# WKUP_CTRL_MMR0_CFG0 register map
Vendor: Texas Instruments
Registers are 32-bit, read-write, reset 0x0 unless marked. A register's access mark holds for its fields unless they carry their own. Offsets are as the file gives them; [hi:lo] are bit positions; {n}, {i} and the like mark numbered series.

## WKUP_CTRL_MMR0_CFG0 (part 6 of 11)
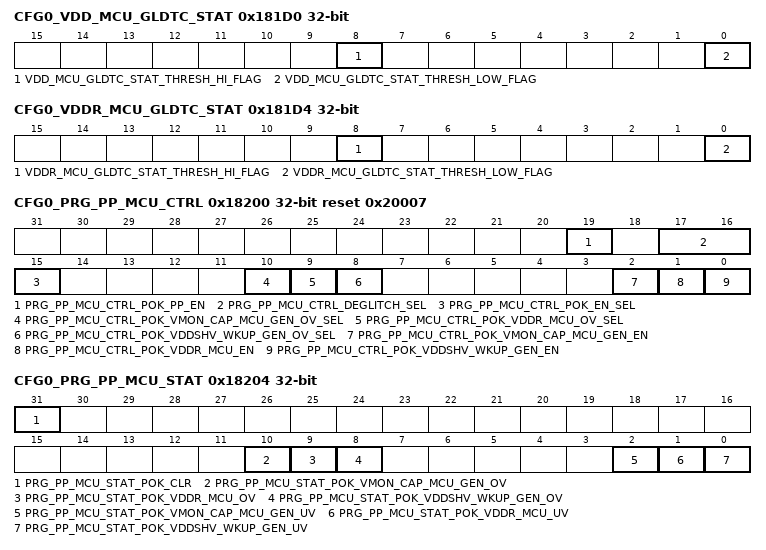
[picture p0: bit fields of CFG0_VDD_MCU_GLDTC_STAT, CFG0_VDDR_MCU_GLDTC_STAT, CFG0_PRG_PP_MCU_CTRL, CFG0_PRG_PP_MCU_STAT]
0x181D0 CFG0_VDD_MCU_GLDTC_STAT ro
  [8] VDD_MCU_GLDTC_STAT_THRESH_HI_FLAG — High voltage flag. This flag is cleared by clearing the VDD_MCU_GLDTC_CTRL_rstb bit. 0 - No high voltage detected 1 - Voltage above the high voltage threshold was detected.
  [0] VDD_MCU_GLDTC_STAT_THRESH_LOW_FLAG — Low voltage flag. This flag is cleared by clearing the VDD_MCU_GLDTC_CTRL_rstb bit. 0 - No low voltage detected 1 - Voltage below the low voltage threshold was detected.
0x181D4 CFG0_VDDR_MCU_GLDTC_STAT ro
  [8] VDDR_MCU_GLDTC_STAT_THRESH_HI_FLAG — High voltage flag. This flag is cleared by clearing the VDDR_MCU_GLDTC_CTRL_rstb bit. 0 - No high voltage detected 1 - Voltage above the high voltage threshold was detected.
  [0] VDDR_MCU_GLDTC_STAT_THRESH_LOW_FLAG — Low voltage flag. This flag is cleared by clearing the VDDR_MCU_GLDTC_CTRL_rstb bit. 0 - No low voltage detected 1 - Voltage below the low voltage threshold was detected.
0x18200 CFG0_PRG_PP_MCU_CTRL reset 0x20007
  [19] PRG_PP_MCU_CTRL_POK_PP_EN — POK ping-pong enable. When set, enables automatic switching between undervoltage and overvoltage detection on VDDSHV_WKUP_GENERAL, VDDR_MCU and VMON_CAP_MCU_GENERAL POKs. This bit has no effect if the POK's ov_sel bit = 1. 0 - No pingpong operation. UV/OV operation selected by each POK ov_sel bit 1 - Pingpong operation enabled .
  [17:16] PRG_PP_MCU_CTRL_DEGLITCH_SEL — Deglitch period for PRG_PP_MCU POKs Field values (others are reserved): 2'b00 - 5 us 2'b01 - 10 us 2'b10 - 15 us 2'b11 - 20 us
  [15] PRG_PP_MCU_CTRL_POK_EN_SEL — Select POK enable source 0 - POK enables come from hardware tie-offs 1 - POK enables come from PRG_PP_MCU_CTRL register
  [10] PRG_PP_MCU_CTRL_POK_VMON_CAP_MCU_GEN_OV_SEL — Force VMON_CAP_MCU_GENERAL POK overvoltage detection. If this bit is 0 and pok_pp_en bit is also 0 then only undervoltage detection is enabled. 0 - Undervoltage detection or UV/OV ping-pong operation 1- Overvoltage detection only
  [9] PRG_PP_MCU_CTRL_POK_VDDR_MCU_OV_SEL — Force VDDR_MCU POK overvoltage detection. If this bit is 0 and pok_pp_en bit is also 0 then only undervoltage detection is enabled. 0 - Undervoltage detection or UV/OV ping-pong operation 1- Overvoltage detection only
  [8] PRG_PP_MCU_CTRL_POK_VDDSHV_WKUP_GEN_OV_SEL — Force VDDSHV_WKUP_GENERAL POK overvoltage detection. If this bit is 0 and pok_pp_en bit is also 0 then only undervoltage detection is enabled. 0 - Undervoltage detection or UV/OV ping-pong operation 1- Overvoltage detection only
  [2] PRG_PP_MCU_CTRL_POK_VMON_CAP_MCU_GEN_EN — Enable VMON_CAP_MCU_GENERAL POK detection 0 - POK detection disabled 1 - POK detection enabled
  [1] PRG_PP_MCU_CTRL_POK_VDDR_MCU_EN — Enable VDDR_MCU POK detection 0 - POK detection disabled 1 - POK detection enabled
  [0] PRG_PP_MCU_CTRL_POK_VDDSHV_WKUP_GEN_EN — Enable VDDSHV_WKUP_GENERAL POK detection 0 - POK detection disabled 1 - POK detection enabled
0x18204 CFG0_PRG_PP_MCU_STAT access per field
  [31] PRG_PP_MCU_STAT_POK_CLR rw — When set, resets pgood sticky bits for VDDSHV_WKUP_GENERAL, VDDR_MCU, and VMON_CAP_MCU_GENERAL voltage POK detection.
  [10] PRG_PP_MCU_STAT_POK_VMON_CAP_MCU_GEN_OV ro — VMON_CAP_MCU_GENERAL overvoltage POK 0 - Voltage good 1 - Voltage above threshold
  [9] PRG_PP_MCU_STAT_POK_VDDR_MCU_OV ro — VDDR_MCU overvoltage POK 0 - Voltage good 1 - Voltage above threshold
  [8] PRG_PP_MCU_STAT_POK_VDDSHV_WKUP_GEN_OV ro — VDDSHV_WKUP_GENERAL overvoltage POK 0 - Voltage good 1 - Voltage above threshold
  [2] PRG_PP_MCU_STAT_POK_VMON_CAP_MCU_GEN_UV ro — VMON_CAP_MCU_GENERAL undervoltage POK 0 - Voltage good 1 - Voltage below threshold
  [1] PRG_PP_MCU_STAT_POK_VDDR_MCU_UV ro — VDDR_MCU undervoltage POK 0 - Voltage good 1 - Voltage below threshold
  [0] PRG_PP_MCU_STAT_POK_VDDSHV_WKUP_GEN_UV ro — VDDSHV_WKUP_GENERAL undervoltage POK 0 - Voltage good 1 - Voltage below threshold
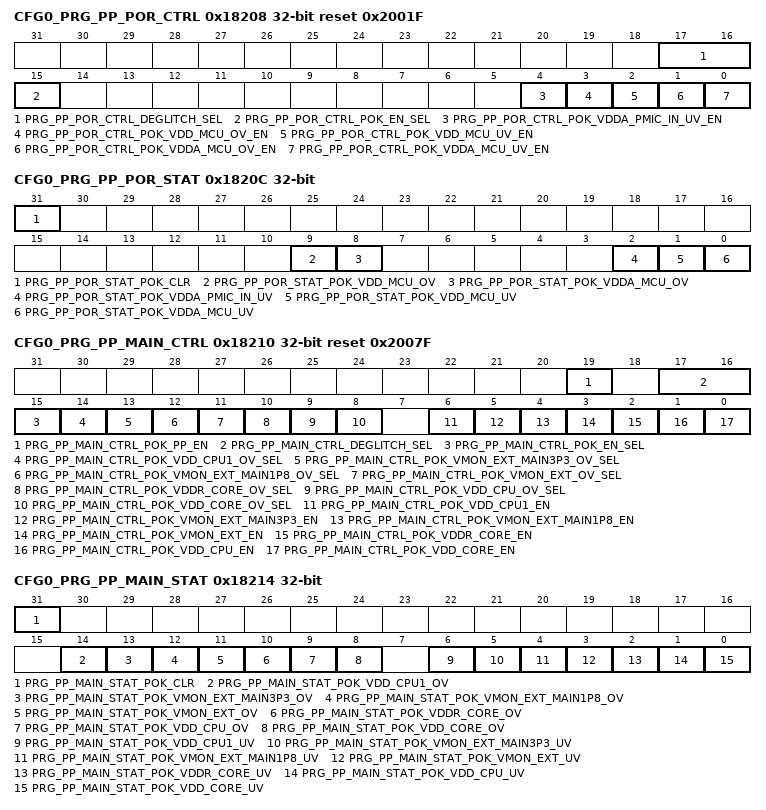
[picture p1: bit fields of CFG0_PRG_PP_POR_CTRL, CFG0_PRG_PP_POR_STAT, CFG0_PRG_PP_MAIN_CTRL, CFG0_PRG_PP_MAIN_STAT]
0x18208 CFG0_PRG_PP_POR_CTRL reset 0x2001F
  [17:16] PRG_PP_POR_CTRL_DEGLITCH_SEL — Deglitch period for PRG_PP_POR POKs Field values (others are reserved): 2'b00 - 5 us 2'b01 - 10 us 2'b10 - 15 us 2'b11 - 20 us
  [15] PRG_PP_POR_CTRL_POK_EN_SEL — Select POK enable source 0 - POK enables come from hardware tie-offs 1 - POK enables come from PRG_PP_POR_CTRL register
  [4] PRG_PP_POR_CTRL_POK_VDDA_PMIC_IN_UV_EN — Enable VDDA_PMIC_IN undervoltage POK detection 0 - POK detection disabled 1 - POK detection enabled
  [3] PRG_PP_POR_CTRL_POK_VDD_MCU_OV_EN — Enable VDD_MCU overvoltage POK detection 0 - POK detection disabled 1 - POK detection enabled
  [2] PRG_PP_POR_CTRL_POK_VDD_MCU_UV_EN — Enable VDD_MCU undervoltage POK detection 0 - POK detection disabled 1 - POK detection enabled
  [1] PRG_PP_POR_CTRL_POK_VDDA_MCU_OV_EN — Enable 1.8V VDDA_MCU overvoltage POK detection 0 - POK detection disabled 1 - POK detection enabled
  [0] PRG_PP_POR_CTRL_POK_VDDA_MCU_UV_EN — Enable 1.8V VDDA_MCU undervoltage POK detection 0 - POK detection disabled 1 - POK detection enabled
0x1820C CFG0_PRG_PP_POR_STAT access per field
  [31] PRG_PP_POR_STAT_POK_CLR rw — When set, resets pgood sticky bits for VDDA_MCU, VDD_MCU, and VDDA_PMIC_IN voltage POK detection.
  [9] PRG_PP_POR_STAT_POK_VDD_MCU_OV ro — VDD_MCU overvoltage POK detection 0 - Voltage good 1 - Voltage above threshold
  [8] PRG_PP_POR_STAT_POK_VDDA_MCU_OV ro — 1.8V VDDA_MCU overvoltage POK detection 0 - Voltage good 1 - Voltage above threshold
  [2] PRG_PP_POR_STAT_POK_VDDA_PMIC_IN_UV ro — VDDA_PMIC_IN undervoltage POK detection 0 - Voltage good 1 - Voltage below threshold
  [1] PRG_PP_POR_STAT_POK_VDD_MCU_UV ro — VDD_MCU undervoltage POK detection 0 - Voltage good 1 - Voltage below threshold
  [0] PRG_PP_POR_STAT_POK_VDDA_MCU_UV ro — 1.8V VDDA_MCU undervoltage POK detection 0 - Voltage good 1 - Voltage below threshold
0x18210 CFG0_PRG_PP_MAIN_CTRL reset 0x2007F
  [19] PRG_PP_MAIN_CTRL_POK_PP_EN — POK ping-pong enable. When set, enables automatic switching between undervoltage and overvoltage detection on VDD_CORE, VDD_CPU, VDDR_CORE, VMON_EXT, VMON_EXT_MAIN1P8 and VMON_EXT_MAIN3P3. This bit has no effect if the POK's ov_sel bit = 1. 0 - No pingpong operation. UV/OV operation selected by each POK ov_sel bit 1 - Pingpong operation enabled .
  [17:16] PRG_PP_MAIN_CTRL_DEGLITCH_SEL — Deglitch period for PRG_PP_MAIN POKs Field values (others are reserved): 2'b00 - 5 us 2'b01 - 10 us 2'b10 - 15 us 2'b11 - 20 us
  [15] PRG_PP_MAIN_CTRL_POK_EN_SEL — Select POK enable source 0 - POK enables come from hardware tie-offs 1 - POK enables come from PRG_PP_MAIN_CTRL register
  [14] PRG_PP_MAIN_CTRL_POK_VDD_CPU1_OV_SEL — Force VDD_CPU1 POK overvoltage detection. If this bit is 0 and pok_pp_en bit is also 0 then only undervoltage detection is enabled. 0 - Undervoltage detection or UV/OV ping-pong operation 1- Overvoltage detection only
  [13] PRG_PP_MAIN_CTRL_POK_VMON_EXT_MAIN3P3_OV_SEL — Force VMON_EXT_MAIN 3.3V POK overvoltage detection. If this bit is 0 and pok_pp_en bit is also 0 then only undervoltage detection is enabled. 0 - Undervoltage detection or UV/OV ping-pong operation 1- Overvoltage detection only
  [12] PRG_PP_MAIN_CTRL_POK_VMON_EXT_MAIN1P8_OV_SEL — Force VMON_EXT_MAIN 1.8V POK overvoltage detection. If this bit is 0 and pok_pp_en bit is also 0 then only undervoltage detection is enabled. 0 - Undervoltage detection or UV/OV ping-pong operation 1- Overvoltage detection only
  [11] PRG_PP_MAIN_CTRL_POK_VMON_EXT_OV_SEL — Force VMON_EXT POK overvoltage detection. If this bit is 0 and pok_pp_en bit is also 0 then only undervoltage detection is enabled. 0 - Undervoltage detection or UV/OV ping-pong operation 1- Overvoltage detection only
  [10] PRG_PP_MAIN_CTRL_POK_VDDR_CORE_OV_SEL — Force VDDR_CORE POK overvoltage detection. If this bit is 0 and pok_pp_en bit is also 0 then only undervoltage detection is enabled. 0 - Undervoltage detection or UV/OV ping-pong operation 1- Overvoltage detection only
  [9] PRG_PP_MAIN_CTRL_POK_VDD_CPU_OV_SEL — Force VDD_CPU POK overvoltage detection. If this bit is 0 and pok_pp_en bit is also 0 then only undervoltage detection is enabled. 0 - Undervoltage detection or UV/OV ping-pong operation 1- Overvoltage detection only
  [8] PRG_PP_MAIN_CTRL_POK_VDD_CORE_OV_SEL — Force VDD_CORE POK overvoltage detection. If this bit is 0 and pok_pp_en bit is also 0 then only undervoltage detection is enabled. 0 - Undervoltage detection or UV/OV ping-pong operation 1- Overvoltage detection only
  [6] PRG_PP_MAIN_CTRL_POK_VDD_CPU1_EN — Enable VDD_CPU1 POK detection 0 - POK detection disabled 1 - POK detection enabled
  [5] PRG_PP_MAIN_CTRL_POK_VMON_EXT_MAIN3P3_EN — Enable VMON_EXT_MAIN 3.3V POK detection 0 - POK detection disabled 1 - POK detection enabled
  [4] PRG_PP_MAIN_CTRL_POK_VMON_EXT_MAIN1P8_EN — Enable VMON_EXT_MAIN 1.8V POK detection 0 - POK detection disabled 1 - POK detection enabled
  [3] PRG_PP_MAIN_CTRL_POK_VMON_EXT_EN — Enable VMON_EXT POK detection 0 - POK detection disabled 1 - POK detection enabled
  [2] PRG_PP_MAIN_CTRL_POK_VDDR_CORE_EN — Enable VDDR_CORE POK detection 0 - POK detection disabled 1 - POK detection enabled
  [1] PRG_PP_MAIN_CTRL_POK_VDD_CPU_EN — Enable VDD_CPU POK detection 0 - POK detection disabled 1 - POK detection enabled
  [0] PRG_PP_MAIN_CTRL_POK_VDD_CORE_EN — Enable VDD_CORE POK detection 0 - POK detection disabled 1 - POK detection enabled
0x18214 CFG0_PRG_PP_MAIN_STAT access per field
  [31] PRG_PP_MAIN_STAT_POK_CLR rw — When set, resets pgood sticky bits for VDD_CORE, VDD_CPU, VDDR_CORE, VMON_EXT, VMON_EXT_MAIN1P8, and VMON_EXT_MAIN3P3 voltage POK detection.
  [14] PRG_PP_MAIN_STAT_POK_VDD_CPU1_OV ro — VDD_CPU1 overvoltage POK 0 - Voltage good 1 - Voltage above threshold
  [13] PRG_PP_MAIN_STAT_POK_VMON_EXT_MAIN3P3_OV ro — VMON_EXT_MAIN 3.3V overvoltage POK 0 - Voltage good 1 - Voltage above threshold
  [12] PRG_PP_MAIN_STAT_POK_VMON_EXT_MAIN1P8_OV ro — VMON_EXT_MAIN 1.8V overvoltage POK 0 - Voltage good 1 - Voltage above threshold
  [11] PRG_PP_MAIN_STAT_POK_VMON_EXT_OV ro — VMON_EXT overvoltage POK 0 - Voltage good 1 - Voltage above threshold
  [10] PRG_PP_MAIN_STAT_POK_VDDR_CORE_OV ro — VDDR_CORE overvoltage POK 0 - Voltage good 1 - Voltage above threshold
  [9] PRG_PP_MAIN_STAT_POK_VDD_CPU_OV ro — VDD_CPU overvoltage POK 0 - Voltage good 1 - Voltage above threshold
  [8] PRG_PP_MAIN_STAT_POK_VDD_CORE_OV ro — VDD_CORE overvoltage POK 0 - Voltage good 1 - Voltage above threshold
  [6] PRG_PP_MAIN_STAT_POK_VDD_CPU1_UV ro — VDD_CPU1 undervoltage POK 0 - Voltage good 1 - Voltage below threshold
  [5] PRG_PP_MAIN_STAT_POK_VMON_EXT_MAIN3P3_UV ro — VMON_EXT_MAIN 3.3V undervoltage POK 0 - Voltage good 1 - Voltage below threshold
  [4] PRG_PP_MAIN_STAT_POK_VMON_EXT_MAIN1P8_UV ro — VMON_EXT_MAIN 1.8V undervoltage POK 0 - Voltage good 1 - Voltage below threshold
  [3] PRG_PP_MAIN_STAT_POK_VMON_EXT_UV ro — VMON_EXT undervoltage POK 0 - Voltage good 1 - Voltage below threshold
  [2] PRG_PP_MAIN_STAT_POK_VDDR_CORE_UV ro — VDDR_CORE undervoltage POK 0 - Voltage good 1 - Voltage below threshold
  [1] PRG_PP_MAIN_STAT_POK_VDD_CPU_UV ro — VDD_CPU undervoltage POK 0 - Voltage good 1 - Voltage below threshold
  [0] PRG_PP_MAIN_STAT_POK_VDD_CORE_UV ro — VDD_CORE undervoltage POK 0 - Voltage good 1 - Voltage below threshold
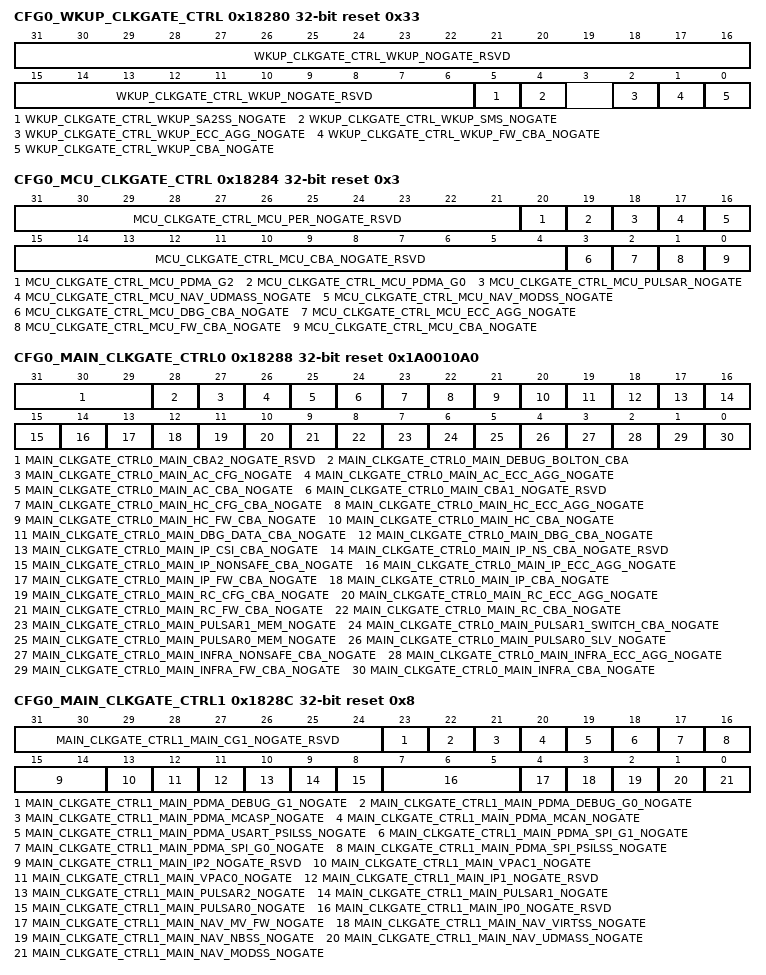
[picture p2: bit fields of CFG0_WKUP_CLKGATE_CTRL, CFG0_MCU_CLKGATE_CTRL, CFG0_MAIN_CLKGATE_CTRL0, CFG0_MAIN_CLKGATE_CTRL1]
0x18280 CFG0_WKUP_CLKGATE_CTRL reset 0x33
  [31:6] WKUP_CLKGATE_CTRL_WKUP_NOGATE_RSVD — WKUP reserved clock gate disable. These bits should remain unchanged (written only with their default value) to maintain compatibility with future devices. 0 - Clocks are gated on idle for power savings 1 - Clocks are not gated on idle, power saving disabled
  [5] WKUP_CLKGATE_CTRL_WKUP_SA2SS_NOGATE — WKUP SA2SS clock gate disable 0 - Clocks are gated on idle for power savings 1 - Clocks are not gated on idle, power saving disabled
  [4] WKUP_CLKGATE_CTRL_WKUP_SMS_NOGATE — WKUP SMS clock gate disable 0 - Clocks are gated on idle for power savings 1 - Clocks are not gated on idle, power saving disabled
  [2] WKUP_CLKGATE_CTRL_WKUP_ECC_AGG_NOGATE — WKUP ECC Aggregator clock gate disable 0 - Clocks are gated on idle for power savings 1 - Clocks are not gated on idle, power saving disabled
  [1] WKUP_CLKGATE_CTRL_WKUP_FW_CBA_NOGATE — WKUP domain Firewall bus (wkup_fw_cbass) clock gate disable 0 - Clocks are gated on idle for power savings 1 - Clocks are not gated on idle, power saving disabled
  [0] WKUP_CLKGATE_CTRL_WKUP_CBA_NOGATE — WKUP domain Data bus (wkup_cbass) clock gate disable 0 - Clocks are gated on idle for power savings 1 - Clocks are not gated on idle, power saving disabled
0x18284 CFG0_MCU_CLKGATE_CTRL reset 0x3
  [31:21] MCU_CLKGATE_CTRL_MCU_PER_NOGATE_RSVD — MCU reserved clock gate disable. These bits should remain unchanged (written only with their default value) to maintain compatibility with future devices. 0 - Clocks are gated on idle for power savings 1 - Clocks are not gated on idle, power saving disabled
  [20] MCU_CLKGATE_CTRL_MCU_PDMA_G2 — MCU domain MCAN1/USART0 PDMA clock gate disable. 0 - Clocks are gated on idle for power savings 1 - Clocks are not gated on idle, power saving disabled
  [19] MCU_CLKGATE_CTRL_MCU_PDMA_G0 — MCU domain MCAN0/SPI0 PDMA clock gate disable. 0 - Clocks are gated on idle for power savings 1 - Clocks are not gated on idle, power saving disabled
  [18] MCU_CLKGATE_CTRL_MCU_PULSAR_NOGATE — MCU domain Pulsar clock gate disable. 0 - Clocks are gated on idle for power savings 1 - Clocks are not gated on idle, power saving disabled
  [17] MCU_CLKGATE_CTRL_MCU_NAV_UDMASS_NOGATE — MCU NavSS UDMA interface clock gate disable. 0 - Clocks are gated on idle for power savings 1 - Clocks are not gated on idle, power saving disabled
  [16] MCU_CLKGATE_CTRL_MCU_NAV_MODSS_NOGATE — MCU NavSS MODSS interface clock gate disable. 0 - Clocks are gated on idle for power savings 1 - Clocks are not gated on idle, power saving disabled
  [15:4] MCU_CLKGATE_CTRL_MCU_CBA_NOGATE_RSVD — MCU reserved clock gate disable. These bits should remain unchanged (written only with their default value) to maintain compatibility with future devices. 0 - Clocks are gated on idle for power savings 1 - Clocks are not gated on idle, power saving disabled
  [3] MCU_CLKGATE_CTRL_MCU_DBG_CBA_NOGATE — MCU domain Debug bus (mcu_dbg_cbass) clock gate disable. 0 - Clocks are gated on idle for power savings 1 - Clocks are not gated on idle, power saving disabled
  [2] MCU_CLKGATE_CTRL_MCU_ECC_AGG_NOGATE — MCU ECC Aggregator clock gate disable 0 - Clocks are gated on idle for power savings 1 - Clocks are not gated on idle, power saving disabled
  [1] MCU_CLKGATE_CTRL_MCU_FW_CBA_NOGATE — MCU domain Firewall bus (mcu_fw_cbass) clock gate disable. 0 - Clocks are gated on idle for power savings 1 - Clocks are not gated on idle, power saving disabled
  [0] MCU_CLKGATE_CTRL_MCU_CBA_NOGATE — MCU domain Data bus (mcu_cbass) clock gate disable. 0 - Clocks are gated on idle for power savings 1 - Clocks are not gated on idle, power saving disabled
0x18288 CFG0_MAIN_CLKGATE_CTRL0 reset 0x1A0010A0
  [31:29] MAIN_CLKGATE_CTRL0_MAIN_CBA2_NOGATE_RSVD — MAIN CBA reserved clock gate disable. These bits should remain unchanged (written only with their default value) to maintain compatibility with future devices. 0 - Clocks are gated on idle for power savings 1 - Clocks are not gated on idle, power saving disabled
  [28] MAIN_CLKGATE_CTRL0_MAIN_DEBUG_BOLTON_CBA — MAIN domain debug bolton bus (debug_bolton_cbass) clock gate disable. 0 - Clocks are gated on idle for power savings 1 - Clocks are not gated on idle, power saving disabled
  [27] MAIN_CLKGATE_CTRL0_MAIN_AC_CFG_NOGATE — MAIN domain AC Configuration bus (ac_cfg_fw_cbass) clock gate disable. 0 - Clocks are gated on idle for power savings 1 - Clocks are not gated on idle, power saving disabled
  [26] MAIN_CLKGATE_CTRL0_MAIN_AC_ECC_AGG_NOGATE — MAIN domain AC ECC aggregator bus (ac_pipe_ecc_aggr) clock gate disable. 0 - Clocks are gated on idle for power savings 1 - Clocks are not gated on idle, power saving disabled
  [25] MAIN_CLKGATE_CTRL0_MAIN_AC_CBA_NOGATE — MAIN domain AC Firewall bus (ac_pipe_cbass_main_fw_cbass_0) clock gate disable. 0 - Clocks are gated on idle for power savings 1 - Clocks are not gated on idle, power saving disabled
  [24] MAIN_CLKGATE_CTRL0_MAIN_CBA1_NOGATE_RSVD — MAIN CBA reserved clock gate disable. These bits should remain unchanged (written only with their default value) to maintain compatibility with future devices. 0 - Clocks are gated on idle for power savings 1 - Clocks are not gated on idle, power saving disabled
  [23] MAIN_CLKGATE_CTRL0_MAIN_HC_CFG_CBA_NOGATE — MAIN domain HC Configuration bus (hc_cfg_cbass_0) clock gate disable. 0 - Clocks are gated on idle for power savings 1 - Clocks are not gated on idle, power saving disabled
  [22] MAIN_CLKGATE_CTRL0_MAIN_HC_ECC_AGG_NOGATE — MAIN domain HC ECC aggregator (nogate) clock gate disable. 0 - Clocks are gated on idle for power savings 1 - Clocks are not gated on idle, power saving disabled
  [21] MAIN_CLKGATE_CTRL0_MAIN_HC_FW_CBA_NOGATE — MAIN domain HC Firewall bus (main_hc2_fw_cbass_0) clock gate disable. 0 - Clocks are gated on idle for power savings 1 - Clocks are not gated on idle, power saving disabled
  [20] MAIN_CLKGATE_CTRL0_MAIN_HC_CBA_NOGATE — MAIN domain HC Data bus (hc2_cbass_0) clock gate disable. 0 - Clocks are gated on idle for power savings 1 - Clocks are not gated on idle, power saving disabled
  [19] MAIN_CLKGATE_CTRL0_MAIN_DBG_DATA_CBA_NOGATE — MAIN domain Debug Data bus (debug_cbass) clock gate disable. 0 - Clocks are gated on idle for power savings 1 - Clocks are not gated on idle, power saving disabled
  [18] MAIN_CLKGATE_CTRL0_MAIN_DBG_CBA_NOGATE — MAIN domain Debug bus (debug_cbass_wrap_main_0) clock gate disable. 0 - Clocks are gated on idle for power savings 1 - Clocks are not gated on idle, power saving disabled
  [17] MAIN_CLKGATE_CTRL0_MAIN_IP_CSI_CBA_NOGATE — MAIN domain CSI bus (csi_cbass_0) clock gate disable. 0 - Clocks are gated on idle for power savings 1 - Clocks are not gated on idle, power saving disabled
  [16] MAIN_CLKGATE_CTRL0_MAIN_IP_NS_CBA_NOGATE_RSVD — MAIN nonsafety CBA reserved clock gate disable. These bits should remain unchanged (written only with their default value) to maintain compatibility with future devices. 0 - Clocks are gated on idle for power savings 1 - Clocks are not gated on idle, power saving disabled
  [15] MAIN_CLKGATE_CTRL0_MAIN_IP_NONSAFE_CBA_NOGATE — MAIN domain Interface Peripheral nonsafety IP bus (ipphy_cbass_0) clock gate disable. 0 - Clocks are gated on idle for power savings 1 - Clocks are not gated on idle, power saving disabled
  [14] MAIN_CLKGATE_CTRL0_MAIN_IP_ECC_AGG_NOGATE — MAIN domain Interface Peripheral ECC aggregator (main_spi0_g0_main_0_ecc_aggr_main_0) clock gate disable. 0 - Clocks are gated on idle for power savings 1 - Clocks are not gated on idle, power saving disabled
  [13] MAIN_CLKGATE_CTRL0_MAIN_IP_FW_CBA_NOGATE — MAIN domain Interface Peripheral Firewall bus (ipphy_cbass_main_fw_cbass) clock gate disable. 0 - Clocks are gated on idle for power savings 1 - Clocks are not gated on idle, power saving disabled
  [12] MAIN_CLKGATE_CTRL0_MAIN_IP_CBA_NOGATE — MAIN domain Interface Peripheral bus (ipphy_safe_cbass_0) clock gate disable. 0 - Clocks are gated on idle for power savings 1 - Clocks are not gated on idle, power saving disabled
  [11] MAIN_CLKGATE_CTRL0_MAIN_RC_CFG_CBA_NOGATE — MAIN domain RC Configuration bus (rc_cfg_cbass_0) clock gate disable. 0 - Clocks are gated on idle for power savings 1 - Clocks are not gated on idle, power saving disabled
  [10] MAIN_CLKGATE_CTRL0_MAIN_RC_ECC_AGG_NOGATE — MAIN domain RC ECC aggregator (main_rc_ecc_aggr_main_0) clock gate disable. 0 - Clocks are gated on idle for power savings 1 - Clocks are not gated on idle, power saving disabled
  [9] MAIN_CLKGATE_CTRL0_MAIN_RC_FW_CBA_NOGATE — MAIN domain RC Firewall bus (rc_cbass_main_fw_cbass) clock gate disable. 0 - Clocks are gated on idle for power savings 1 - Clocks are not gated on idle, power saving disabled
  [8] MAIN_CLKGATE_CTRL0_MAIN_RC_CBA_NOGATE — MAIN domain RC Data bus (rc_cbass_0) clock gate disable. 0 - Clocks are gated on idle for power savings 1 - Clocks are not gated on idle, power saving disabled
  [7] MAIN_CLKGATE_CTRL0_MAIN_PULSAR1_MEM_NOGATE — MAIN domain Pulsar 1 memory bus (pulsar1_mem_cbass) clock gate disable. 0 - Clocks are gated on idle for power savings 1 - Clocks are not gated on idle, power saving disabled
  [6] MAIN_CLKGATE_CTRL0_MAIN_PULSAR1_SWITCH_CBA_NOGATE — MAIN domain Pulsar 1 peripheral switch bus (pulsar1_periph_switch_cbass) clock gate disable. 0 - Clocks are gated on idle for power savings 1 - Clocks are not gated on idle, power saving disabled
  [5] MAIN_CLKGATE_CTRL0_MAIN_PULSAR0_MEM_NOGATE — MAIN domain Pulsar 0 memory bus (pulsar0_mem_cbass) clock gate disable. 0 - Clocks are gated on idle for power savings 1 - Clocks are not gated on idle, power saving disabled
  [4] MAIN_CLKGATE_CTRL0_MAIN_PULSAR0_SLV_NOGATE — MAIN domain Pulsar slave bus (pulsar0_slv_cbass) clock gate disable. 0 - Clocks are gated on idle for power savings 1 - Clocks are not gated on idle, power saving disabled
  [3] MAIN_CLKGATE_CTRL0_MAIN_INFRA_NONSAFE_CBA_NOGATE — MAIN domain Infrastructure non-safety IP bus (main_infra_non_safe_cbass) clock gate disable. 0 - Clocks are gated on idle for power savings 1 - Clocks are not gated on idle, power saving disabled
  [2] MAIN_CLKGATE_CTRL0_MAIN_INFRA_ECC_AGG_NOGATE — MAIN domain Infrastructure ECC aggregator (main_infra_ecc_aggr) clock gate disable. 0 - Clocks are gated on idle for power savings 1 - Clocks are not gated on idle, power saving disabled
  [1] MAIN_CLKGATE_CTRL0_MAIN_INFRA_FW_CBA_NOGATE — MAIN domain Infrastructure Firewall bus (main_infra_fw_cbass) clock gate disable. 0 - Clocks are gated on idle for power savings 1 - Clocks are not gated on idle, power saving disabled
  [0] MAIN_CLKGATE_CTRL0_MAIN_INFRA_CBA_NOGATE — MAIN domain Infrastructure bus (main_infra_cbass) clock gate disable. 0 - Clocks are gated on idle for power savings 1 - Clocks are not gated on idle, power saving disabled
0x1828C CFG0_MAIN_CLKGATE_CTRL1 reset 0x8
  [31:24] MAIN_CLKGATE_CTRL1_MAIN_CG1_NOGATE_RSVD — MAIN PDMA clock gate disable. These bits should remain unchanged (written only with their default value) to maintain compatibility with future devices. 0 - Clocks are gated on idle for power savings 1 - Clocks are not gated on idle, power saving disabled
  [23] MAIN_CLKGATE_CTRL1_MAIN_PDMA_DEBUG_G1_NOGATE — MAIN domain PDMA Debug_G1 clock gate disable. 0 - Clocks are gated on idle for power savings 1 - Clocks are not gated on idle, power saving disabled
  [22] MAIN_CLKGATE_CTRL1_MAIN_PDMA_DEBUG_G0_NOGATE — MAIN domain PDMA Debug_G0 clock gate disable. 0 - Clocks are gated on idle for power savings 1 - Clocks are not gated on idle, power saving disabled
  [21] MAIN_CLKGATE_CTRL1_MAIN_PDMA_MCASP_NOGATE — MAIN domain PDMA MCASP clock gate disable. 0 - Clocks are gated on idle for power savings 1 - Clocks are not gated on idle, power saving disabled
  [20] MAIN_CLKGATE_CTRL1_MAIN_PDMA_MCAN_NOGATE — MAIN domain PDMA MCAN clock gate disable. 0 - Clocks are gated on idle for power savings 1 - Clocks are not gated on idle, power saving disabled
  [19] MAIN_CLKGATE_CTRL1_MAIN_PDMA_USART_PSILSS_NOGATE — MAIN domain PDMA USART PSILSS clock gate disable. 0 - Clocks are gated on idle for power savings 1 - Clocks are not gated on idle, power saving disabled
  [18] MAIN_CLKGATE_CTRL1_MAIN_PDMA_SPI_G1_NOGATE — MAIN domain PDMA SPI_G1 clock gate disable. 0 - Clocks are gated on idle for power savings 1 - Clocks are not gated on idle, power saving disabled
  [17] MAIN_CLKGATE_CTRL1_MAIN_PDMA_SPI_G0_NOGATE — MAIN domain PDMA SPI_G0 clock gate disable. 0 - Clocks are gated on idle for power savings 1 - Clocks are not gated on idle, power saving disabled
  [16] MAIN_CLKGATE_CTRL1_MAIN_PDMA_SPI_PSILSS_NOGATE — MAIN domain PDMA SPI PSILSS clock gate disable. 0 - Clocks are gated on idle for power savings 1 - Clocks are not gated on idle, power saving disabled
  [15:14] MAIN_CLKGATE_CTRL1_MAIN_IP2_NOGATE_RSVD — MAIN IP reserved clock gate disable. These bits should remain unchanged (written only with their default value) to maintain compatibility with future devices. 0 - Clocks are gated on idle for power savings 1 - Clocks are not gated on idle, power saving disabled
  [13] MAIN_CLKGATE_CTRL1_MAIN_VPAC1_NOGATE — MAIN domain VPAC 1 clock gate disable. 0 - Clocks are gated on idle for power savings 1 - Clocks are not gated on idle, power saving disabled
  [12] MAIN_CLKGATE_CTRL1_MAIN_VPAC0_NOGATE — MAIN domain VPAC 0 clock gate disable. 0 - Clocks are gated on idle for power savings 1 - Clocks are not gated on idle, power saving disabled
  [11] MAIN_CLKGATE_CTRL1_MAIN_IP1_NOGATE_RSVD — MAIN IP reserved clock gate disable. These bits should remain unchanged (written only with their default value) to maintain compatibility with future devices. 0 - Clocks are gated on idle for power savings 1 - Clocks are not gated on idle, power saving disabled
  [10] MAIN_CLKGATE_CTRL1_MAIN_PULSAR2_NOGATE — MAIN domain Pulsar 2 clock gate disable. 0 - Clocks are gated on idle for power savings 1 - Clocks are not gated on idle, power saving disabled
  [9] MAIN_CLKGATE_CTRL1_MAIN_PULSAR1_NOGATE — MAIN domain Pulsar 1 clock gate disable. 0 - Clocks are gated on idle for power savings 1 - Clocks are not gated on idle, power saving disabled
  [8] MAIN_CLKGATE_CTRL1_MAIN_PULSAR0_NOGATE — MAIN domain Pulsar 0 clock gate disable. 0 - Clocks are gated on idle for power savings 1 - Clocks are not gated on idle, power saving disabled
  [7:5] MAIN_CLKGATE_CTRL1_MAIN_IP0_NOGATE_RSVD — MAIN IP reserved clock gate disable. These bits should remain unchanged (written only with their default value) to maintain compatibility with future devices. 0 - Clocks are gated on idle for power savings 1 - Clocks are not gated on idle, power saving disabled
  [4] MAIN_CLKGATE_CTRL1_MAIN_NAV_MV_FW_NOGATE — MAIN NavSS Mod/Virt Firewall interface clock gate disable. 0 - Clocks are gated on idle for power savings 1 - Clocks are not gated on idle, power saving disabled
  [3] MAIN_CLKGATE_CTRL1_MAIN_NAV_VIRTSS_NOGATE — MAIN NavSS VIRTSS interface clock gate disable. 0 - Clocks are gated on idle for power savings 1 - Clocks are not gated on idle, power saving disabled
  [2] MAIN_CLKGATE_CTRL1_MAIN_NAV_NBSS_NOGATE — MAIN NavSS NB interface clock gate disable. 0 - Clocks are gated on idle for power savings 1 - Clocks are not gated on idle, power saving disabled
  [1] MAIN_CLKGATE_CTRL1_MAIN_NAV_UDMASS_NOGATE — Main NavSS UDMA interface clock gate disable. 0 - Clocks are gated on idle for power savings 1 - Clocks are not gated on idle, power saving disabled
  [0] MAIN_CLKGATE_CTRL1_MAIN_NAV_MODSS_NOGATE — MAIN NavSS MODSS interface clock gate disable. 0 - Clocks are gated on idle for power savings 1 - Clocks are not gated on idle, power saving disabled
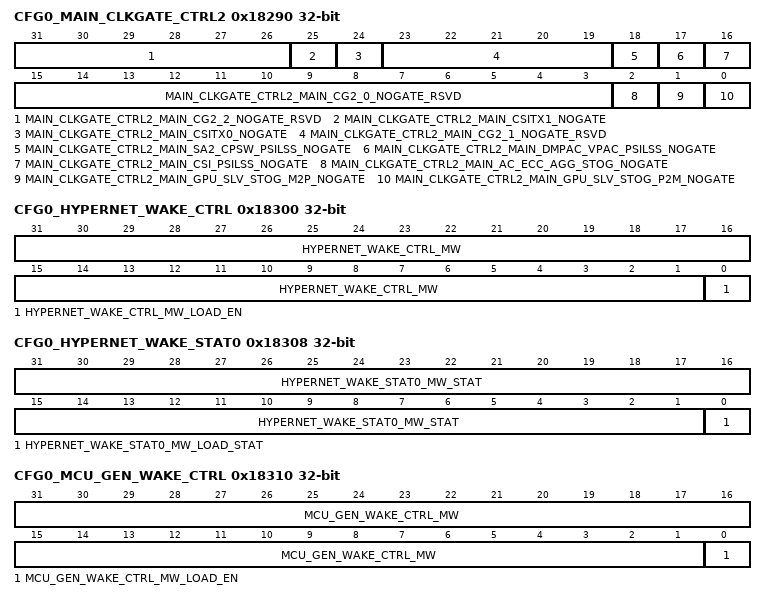
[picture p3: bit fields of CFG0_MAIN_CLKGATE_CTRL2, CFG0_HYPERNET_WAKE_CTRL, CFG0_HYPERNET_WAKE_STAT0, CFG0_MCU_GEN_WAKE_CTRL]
0x18290 CFG0_MAIN_CLKGATE_CTRL2
  [31:26] MAIN_CLKGATE_CTRL2_MAIN_CG2_2_NOGATE_RSVD — MAIN domain spare clock gate disable. These bits should remain unchanged (written only with their default value) to maintain compatibility with future devices. 0 - Clocks are gated on idle for power savings 1 - Clocks are not gated on idle, power saving disabled
  [25] MAIN_CLKGATE_CTRL2_MAIN_CSITX1_NOGATE — MAIN domain CSI_TX1 clock gate disable. 0 - Clocks are gated on idle for power savings 1 - Clocks are not gated on idle, power saving disabled
  [24] MAIN_CLKGATE_CTRL2_MAIN_CSITX0_NOGATE — MAIN domain CSI_TX0 clock gate disable. 0 - Clocks are gated on idle for power savings 1 - Clocks are not gated on idle, power saving disabled
  [23:19] MAIN_CLKGATE_CTRL2_MAIN_CG2_1_NOGATE_RSVD — MAIN domain spare clock gate disable. These bits should remain unchanged (written only with their default value) to maintain compatibility with future devices. 0 - Clocks are gated on idle for power savings 1 - Clocks are not gated on idle, power saving disabled
  [18] MAIN_CLKGATE_CTRL2_MAIN_SA2_CPSW_PSILSS_NOGATE — MAIN domain SA2_UL/SPCW PSILSS clock gate disable. 0 - Clocks are gated on idle for power savings 1 - Clocks are not gated on idle, power saving disabled
  [17] MAIN_CLKGATE_CTRL2_MAIN_DMPAC_VPAC_PSILSS_NOGATE — MAIN domain DMPAC/VPAC PSILSS clock gate disable. 0 - Clocks are gated on idle for power savings 1 - Clocks are not gated on idle, power saving disabled
  [16] MAIN_CLKGATE_CTRL2_MAIN_CSI_PSILSS_NOGATE — MAIN domain CSI PSILSS clock gate disable. 0 - Clocks are gated on idle for power savings 1 - Clocks are not gated on idle, power saving disabled
  [15:3] MAIN_CLKGATE_CTRL2_MAIN_CG2_0_NOGATE_RSVD — MAIN domain spare clock gate disable. These bits should remain unchanged (written only with their default value) to maintain compatibility with future devices. 0 - Clocks are gated on idle for power savings 1 - Clocks are not gated on idle, power saving disabled
  [2] MAIN_CLKGATE_CTRL2_MAIN_AC_ECC_AGG_STOG_NOGATE — MAIN domain ac ECC aggregator Slave Timeout Gasket (main_ac_ecc_aggr_stog) clock gate disable. 0 - Clocks are gated on idle for power savings 1 - Clocks are not gated on idle, power saving disabled
  [1] MAIN_CLKGATE_CTRL2_MAIN_GPU_SLV_STOG_M2P_NOGATE — MAIN domain GPU Slave Timeout Gasket output (main_gpu_slv_stog_m2p_pwr_dis) clock gate disable. 0 - Clocks are gated on idle for power savings 1 - Clocks are not gated on idle, power saving disabled
  [0] MAIN_CLKGATE_CTRL2_MAIN_GPU_SLV_STOG_P2M_NOGATE — MAIN domain GPU Slave Timeout Gasket input (main_gpu_slv_stog_p2m_pwr_dis) clock gate disable. 0 - Clocks are gated on idle for power savings 1 - Clocks are not gated on idle, power saving disabled
0x18294 CFG0_MAIN_CLKGATE_CTRL3
  [31:0] MAIN_CLKGATE_CTRL3_MAIN_CG3_NOGATE_RSVD — MAIN domain spare clock gate disable. These bits should remain unchanged (written only with their default value) to maintain compatibility with future devices. 0 - Clocks are gated on idle for power savings 1 - Clocks are not gated on idle, power saving disabled
0x18300 CFG0_HYPERNET_WAKE_CTRL
  [31:1] HYPERNET_WAKE_CTRL_MW — HYPERNET IO magic word. This 31-bit value that enables placing of the HYPERNET I/Os into isolation for daisy-chain wakeup operation. 0x5555 - Magic word value to enable isolation when qualified with mw_load bit Others - Any other value will prevent isolation when mw_load transitions from 0 to 1.
  [0] HYPERNET_WAKE_CTRL_MW_LOAD_EN — Magic word load enable Setting this bit to 1 loads and locks the mw field for HYPERNET IO isolation. If the mw field matches the magic word value then the value is latched into the HYPERNET IO voltage domain and HYPERNET IO isolation is enabled. 0 - Unlock and do not load mw value for comparison 1 - Load and lock mw for magic word value comparison
0x18308 CFG0_HYPERNET_WAKE_STAT0 ro
  [31:1] HYPERNET_WAKE_STAT0_MW_STAT — HYPERNET magic word status Indicates the latched value of the mw field.
  [0] HYPERNET_WAKE_STAT0_MW_LOAD_STAT — Magic word load status. Indicates the latched value of the mw_load_en bit
0x1830C CFG0_HYPERNET_WAKE_STAT1 ro
  [0] HYPERNET_WAKE_STAT1_HYPERNET_IO_MODE — Indicates if HYPERNET IO wakeup mode is enabled. 0 - Not enabled (load_en not set or mw doesn't match magic word) 1 - HYPERNET IO mode enabled
0x18310 CFG0_MCU_GEN_WAKE_CTRL
  [31:1] MCU_GEN_WAKE_CTRL_MW — MCU_GENERAL IO magic word. This 31-bit value that enables placing of the MCU_GENERAL I/Os into isolation for daisy-chain wakeup operation. 0x5555 - Magic word value to enable isolation when qualified with mw_load bit Others - Any other value will prevent isolation when mw_load transitions from 0 to 1.
  [0] MCU_GEN_WAKE_CTRL_MW_LOAD_EN — Magic word load enable Setting this bit to 1 loads and locks the mw field for MCU_GENERAL IO isolation. If the mw field matches the magic word value then the value is latched into the MCU_GENERAL IO voltage domain and MCU_GENERAL IO isolation is enabled. 0 - Unlock and do not load mw value for comparison 1 - Load and lock mw for magic word value comparison
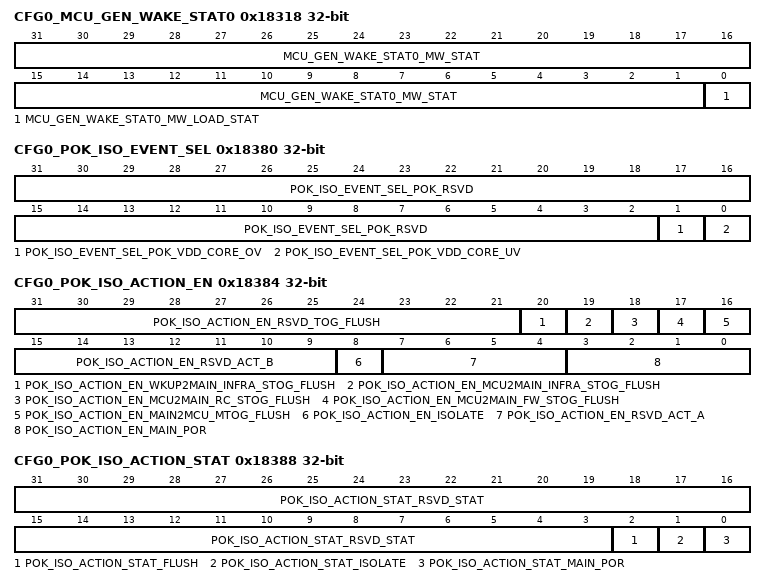
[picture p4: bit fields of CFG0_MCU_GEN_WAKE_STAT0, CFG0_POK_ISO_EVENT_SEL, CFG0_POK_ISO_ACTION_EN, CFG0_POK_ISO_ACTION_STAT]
0x18318 CFG0_MCU_GEN_WAKE_STAT0 ro
  [31:1] MCU_GEN_WAKE_STAT0_MW_STAT — MCU_GENERAL magic word status Indicates the latched value of the mw field.
  [0] MCU_GEN_WAKE_STAT0_MW_LOAD_STAT — Magic word load status. Indicates the latched value of the mw_load_en bit
0x1831C CFG0_MCU_GEN_WAKE_STAT1 ro
  [0] MCU_GEN_WAKE_STAT1_MCU_GEN_IO_MODE — Indicates if MCU_GENERAL IO wakeup mode is enabled. 0 - Not enabled (load_en not set or mw doesn't match magic word) 1 - MCU_GENERAL IO mode enabled
0x18380 CFG0_POK_ISO_EVENT_SEL
  [31:2] POK_ISO_EVENT_SEL_POK_RSVD — Reserved for future use (do not optimize out)
  [1] POK_ISO_EVENT_SEL_POK_VDD_CORE_OV — VDD_CORE overvoltage detection triggers enabled isolation actions
  [0] POK_ISO_EVENT_SEL_POK_VDD_CORE_UV — VDD_CORE undervoltage detection triggers enabled isolation actions
0x18384 CFG0_POK_ISO_ACTION_EN
  [31:21] POK_ISO_ACTION_EN_RSVD_TOG_FLUSH — Reserved timeout gasket flush enable bits. Do not optimize out 0 - Enabled POK events have no effect on this gasket 1 - Enabled POK events will assert the flush for this gasket
  [20] POK_ISO_ACTION_EN_WKUP2MAIN_INFRA_STOG_FLUSH — WKUP to Main INFRA slave timeout gasket flush enable: 0 - Enabled POK events have no effect on this gasket 1 - Enabled POK events will assert the flush for this gasket
  [19] POK_ISO_ACTION_EN_MCU2MAIN_INFRA_STOG_FLUSH — MCU to Main INFRA slave timeout gasket flush enable: 0 - Enabled POK events have no effect on this gasket 1 - Enabled POK events will assert the flush for this gasket
  [18] POK_ISO_ACTION_EN_MCU2MAIN_RC_STOG_FLUSH — MCU to Main RC slave timeout gasket flush enable: 0 - Enabled POK events have no effect on this gasket 1 - Enabled POK events will assert the flush for this gasket
  [17] POK_ISO_ACTION_EN_MCU2MAIN_FW_STOG_FLUSH — MCU to Main FW slave timeout gasket flush enable: 0 - Enabled POK events have no effect on this gasket 1 - Enabled POK events will assert the flush for this gasket
  [16] POK_ISO_ACTION_EN_MAIN2MCU_MTOG_FLUSH — MAIN to MCU master timeout gasket flush enable: 0 - Enabled POK events have no effect on this gasket 1 - Enabled POK events will assert the flush for this gasket
  [15:9] POK_ISO_ACTION_EN_RSVD_ACT_B — Reserved isolation action enable bits. Do not optimize out
  [8] POK_ISO_ACTION_EN_ISOLATE — If enabled, the isolate signal will be asserted after all enabled flush signals have been asserted for 4 of their respective time-out gasket clocks when any selected POK event occurs. 0 - Isolation is not asserted on selected POK event 1 - Isolation signal is asserted on selected POK event after enabled TOG flush
  [7:4] POK_ISO_ACTION_EN_RSVD_ACT_A — Reserved isolation action enable bits. Do not optimize out
  [3:0] POK_ISO_ACTION_EN_MAIN_POR — When set to 4'b0110, MAIN_PORz reset is asserted when any selected POK event occurs. (Reserved for future use, do not optimize out)
0x18388 CFG0_POK_ISO_ACTION_STAT ro
  [31:3] POK_ISO_ACTION_STAT_RSVD_STAT — Reserved POK action status - do not optimize out
  [2] POK_ISO_ACTION_STAT_FLUSH — POK activated timeout gasket flush status This signal will remain asserted until a 1 is written to the POK_ISO_ACTION_CLR_flush bit. 0 - No gasket flush is being asserted by enabled POK event 1 - Enabled gasket flush signals are being asserted due to an enabled POK event
  [1] POK_ISO_ACTION_STAT_ISOLATE — POK activated Isolate status This signal will remain asserted until a 1 is written to the POK_ISO_ACTION_CLR_isolate bit. 0 - No isolate is being asserted by enabled POK event 1 - Isolate signal is being asserted due to an enabled POK event
  [0] POK_ISO_ACTION_STAT_MAIN_POR — Reserved POK activated MAIN_PORz status - do not optimize out 0 - No MAIN_PORz is being asserted by enabled POK event 1 - MAIN_PORz is being asserted due to an enabled POK event
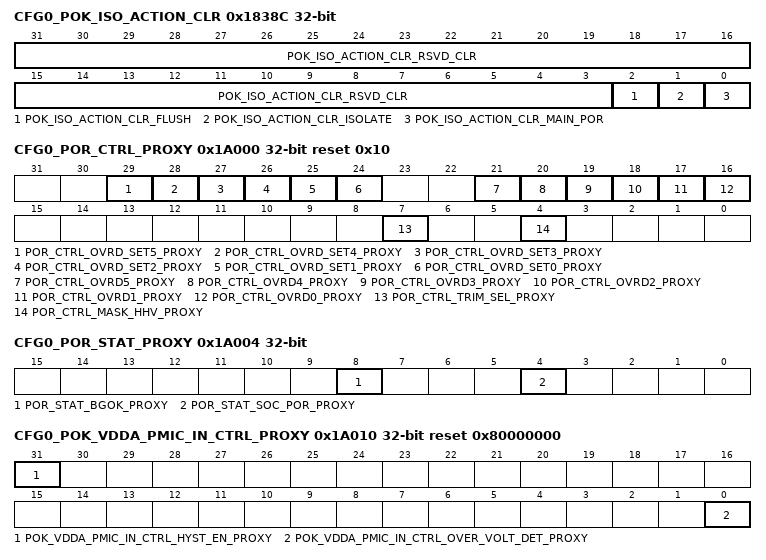
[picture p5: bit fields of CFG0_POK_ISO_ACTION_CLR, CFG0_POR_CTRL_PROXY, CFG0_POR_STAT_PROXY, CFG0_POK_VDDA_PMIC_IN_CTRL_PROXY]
0x1838C CFG0_POK_ISO_ACTION_CLR
  [31:3] POK_ISO_ACTION_CLR_RSVD_CLR — Reserved POK activated signal clear - do not optimize out Always read as 0. Writing 1 deasserts POK activated signal. 0 - Writing 0 has no effect. Bit always reads as 0 1 - Deassert signal. Bit will clear to 0 after write.
  [2] POK_ISO_ACTION_CLR_FLUSH — POK activated timeout gasket flush clear Always read as 0. Writing 1 deasserts POK activated timeot gasket flush signals. 0 - Writing 0 has no effect. Bit always reads as 0 1 - Deassert gasket flush signals. Bit will clear to 0 after write.
  [1] POK_ISO_ACTION_CLR_ISOLATE — POK activated isolate clear Always read as 0. Writing 1 deasserts POK activated isolate signal. 0 - Writing 0 has no effect. Bit always reads as 0 1 - Deassert isolate signal. Bit will clear to 0 after write.
  [0] POK_ISO_ACTION_CLR_MAIN_POR — Reserved POK activated MAIN_PORz clear - do not optimize out Always read as 0. Writing 1 deasserts POK activated MAIN_PORz signal. 0 - Writing 0 has no effect. Bit always reads as 0 1 - Deassert MAIN_PORz. Bit will clear to 0 after write.
0x18390 CFG0_POK_ISO_GP_CTRL
  [31:0] POK_ISO_GP_CTRL_RSVD_CTRL — Reserved POK isolation control bits
0x18394 CFG0_POK_ISO_GP_STAT ro
  [31:0] POK_ISO_GP_STAT_RSVD_STAT — Reserved POK isolation status bits
{0x19100+4i} CFG0_CLAIMREG_P6_R{i}_READONLY ro (i=0..7)
  [31:0] CLAIMREG_P6_R{i}_READONLY — Claim bits for Partition 6
0x1A000 CFG0_POR_CTRL_PROXY reset 0x10
  [29] POR_CTRL_OVRD_SET5_PROXY — Reserved override set
  [28] POR_CTRL_OVRD_SET4_PROXY — POKLVB override set
  [27] POR_CTRL_OVRD_SET3_PROXY — POKLVA override set
  [26] POR_CTRL_OVRD_SET2_PROXY — POKHV override set
  [25] POR_CTRL_OVRD_SET1_PROXY — BGOK override set
  [24] POR_CTRL_OVRD_SET0_PROXY — PORHV override set
  [21] POR_CTRL_OVRD5_PROXY — Reserved override enable
  [20] POR_CTRL_OVRD4_PROXY — POKLVB override enable
  [19] POR_CTRL_OVRD3_PROXY — POKLVA override enable
  [18] POR_CTRL_OVRD2_PROXY — POKHV override enable
  [17] POR_CTRL_OVRD1_PROXY — BGOK override enable
  [16] POR_CTRL_OVRD0_PROXY — PORHV override enable
  [7] POR_CTRL_TRIM_SEL_PROXY — POR Trim Select 0 - Trim selections for Bandgap and POKs come from HHV defaults 1 - Trim selections for Bandgap and POKs come from POR_BANDGAP_CTRL and POR_POKxxx_CTRL registers
  [4] POR_CTRL_MASK_HHV_PROXY — Mask HHV/SOC_PORz outputs when applying new trim values
0x1A004 CFG0_POR_STAT_PROXY ro
  [8] POR_STAT_BGOK_PROXY — Bandgap OK status
  [4] POR_STAT_SOC_POR_PROXY — POR module status 0 - Module is in functional mode 1 - Module is in reset mode
0x1A010 CFG0_POK_VDDA_PMIC_IN_CTRL_PROXY reset 0x80000000
  [31] POK_VDDA_PMIC_IN_CTRL_HYST_EN_PROXY — Enable POK hysteresis
  [0] POK_VDDA_PMIC_IN_CTRL_OVER_VOLT_DET_PROXY — Over / under voltage detection mode 0 - Under voltage detection 1 - Over voltage detection
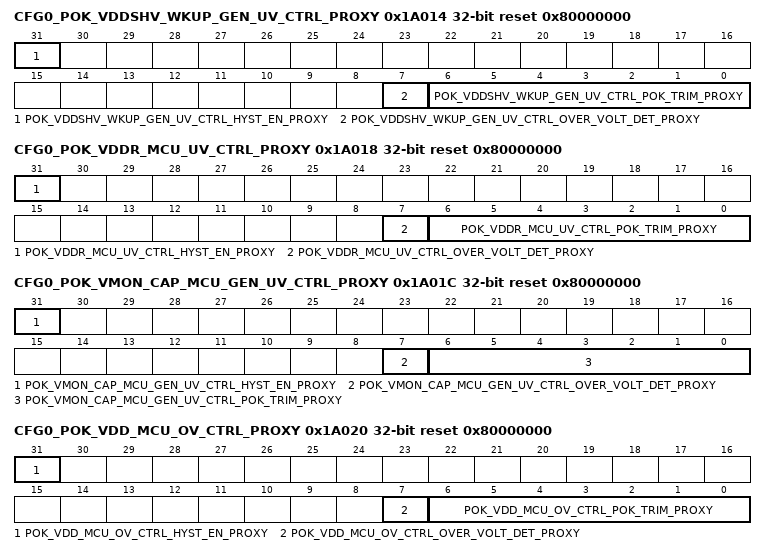
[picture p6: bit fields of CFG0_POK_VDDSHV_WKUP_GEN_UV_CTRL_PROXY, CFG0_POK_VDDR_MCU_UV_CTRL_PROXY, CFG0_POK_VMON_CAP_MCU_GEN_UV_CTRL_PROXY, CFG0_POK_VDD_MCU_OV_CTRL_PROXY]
0x1A014 CFG0_POK_VDDSHV_WKUP_GEN_UV_CTRL_PROXY reset 0x80000000
  [31] POK_VDDSHV_WKUP_GEN_UV_CTRL_HYST_EN_PROXY — Enable POK hysteresis
  [7] POK_VDDSHV_WKUP_GEN_UV_CTRL_OVER_VOLT_DET_PROXY — Over / under voltage detection mode 0 - Under voltage detection 1 - Over voltage detection
  [6:0] POK_VDDSHV_WKUP_GEN_UV_CTRL_POK_TRIM_PROXY — POK trim bits. These bits are used to trim the comparator threshold voltage. See POK spec and J7 efuse spec for details
0x1A018 CFG0_POK_VDDR_MCU_UV_CTRL_PROXY reset 0x80000000
  [31] POK_VDDR_MCU_UV_CTRL_HYST_EN_PROXY — Enable POK hysteresis
  [7] POK_VDDR_MCU_UV_CTRL_OVER_VOLT_DET_PROXY — Over / under voltage detection mode 0 - Under voltage detection 1 - Over voltage detection
  [6:0] POK_VDDR_MCU_UV_CTRL_POK_TRIM_PROXY — POK trim bits. These bits are used to trim the comparator threshold voltage. See POK spec and J7 efuse spec for details
0x1A01C CFG0_POK_VMON_CAP_MCU_GEN_UV_CTRL_PROXY reset 0x80000000
  [31] POK_VMON_CAP_MCU_GEN_UV_CTRL_HYST_EN_PROXY — Enable POK hysteresis
  [7] POK_VMON_CAP_MCU_GEN_UV_CTRL_OVER_VOLT_DET_PROXY — Over / under voltage detection mode 0 - Under voltage detection 1 - Over voltage detection
  [6:0] POK_VMON_CAP_MCU_GEN_UV_CTRL_POK_TRIM_PROXY — POK trim bits. These bits are used to trim the comparator threshold voltage. See POK spec and efuse spec for details
0x1A020 CFG0_POK_VDD_MCU_OV_CTRL_PROXY reset 0x80000000
  [31] POK_VDD_MCU_OV_CTRL_HYST_EN_PROXY — Enable POK hysteresis
  [7] POK_VDD_MCU_OV_CTRL_OVER_VOLT_DET_PROXY — Over / under voltage detection mode 0 - Under voltage detection 1 - Over voltage detection
  [6:0] POK_VDD_MCU_OV_CTRL_POK_TRIM_PROXY — POK trim bits. These bits are used to trim the comparator threshold voltage. See POK spec and J7 efuse spec for details
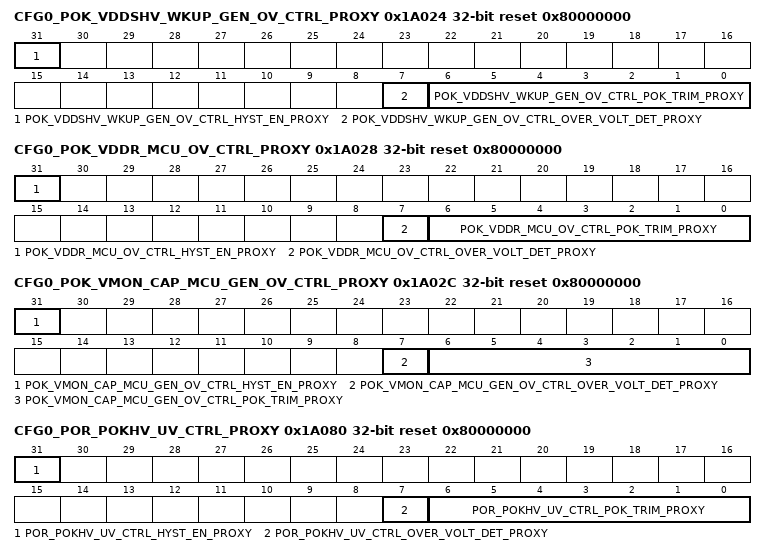
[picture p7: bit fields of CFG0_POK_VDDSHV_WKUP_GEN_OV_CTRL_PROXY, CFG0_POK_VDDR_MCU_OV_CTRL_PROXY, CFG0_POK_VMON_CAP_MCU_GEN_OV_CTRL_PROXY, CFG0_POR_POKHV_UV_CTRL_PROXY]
0x1A024 CFG0_POK_VDDSHV_WKUP_GEN_OV_CTRL_PROXY reset 0x80000000
  [31] POK_VDDSHV_WKUP_GEN_OV_CTRL_HYST_EN_PROXY — Enable POK hysteresis
  [7] POK_VDDSHV_WKUP_GEN_OV_CTRL_OVER_VOLT_DET_PROXY — Over / under voltage detection mode 0 - Under voltage detection 1 - Over voltage detection
  [6:0] POK_VDDSHV_WKUP_GEN_OV_CTRL_POK_TRIM_PROXY — POK trim bits. These bits are used to trim the comparator threshold voltage. See POK spec and J7 efuse spec for details
0x1A028 CFG0_POK_VDDR_MCU_OV_CTRL_PROXY reset 0x80000000
  [31] POK_VDDR_MCU_OV_CTRL_HYST_EN_PROXY — Enable POK hysteresis
  [7] POK_VDDR_MCU_OV_CTRL_OVER_VOLT_DET_PROXY — Over / under voltage detection mode 0 - Under voltage detection 1 - Over voltage detection
  [6:0] POK_VDDR_MCU_OV_CTRL_POK_TRIM_PROXY — POK trim bits. These bits are used to trim the comparator threshold voltage. See POK spec and J7 efuse spec for details
0x1A02C CFG0_POK_VMON_CAP_MCU_GEN_OV_CTRL_PROXY reset 0x80000000
  [31] POK_VMON_CAP_MCU_GEN_OV_CTRL_HYST_EN_PROXY — Enable POK hysteresis
  [7] POK_VMON_CAP_MCU_GEN_OV_CTRL_OVER_VOLT_DET_PROXY — Over / under voltage detection mode 0 - Under voltage detection 1 - Over voltage detection
  [6:0] POK_VMON_CAP_MCU_GEN_OV_CTRL_POK_TRIM_PROXY — POK trim bits. These bits are used to trim the comparator threshold voltage. See POK spec and efuse spec for details
0x1A070 CFG0_MAIN_VDOM_CTRL_PROXY
  [0] MAIN_VDOM_CTRL_MAIN_VD_OFF_PROXY — MAIN deep sleep isolation enable. This bit should be set prior to powering off the MAIN voltage domain to ensure proper signal isolation.
0x1A080 CFG0_POR_POKHV_UV_CTRL_PROXY reset 0x80000000
  [31] POR_POKHV_UV_CTRL_HYST_EN_PROXY — Enable POK hysteresis
  [7] POR_POKHV_UV_CTRL_OVER_VOLT_DET_PROXY — Over / under voltage detection mode 0 - Under voltage detection 1 - Over voltage detection
  [6:0] POR_POKHV_UV_CTRL_POK_TRIM_PROXY — POK trim bits. These bits are used to trim the comparator threshold voltage. See POK spec and J7 efuse spec for details
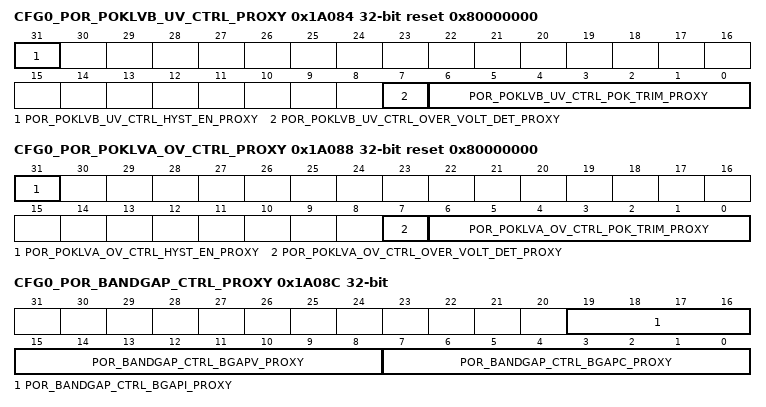
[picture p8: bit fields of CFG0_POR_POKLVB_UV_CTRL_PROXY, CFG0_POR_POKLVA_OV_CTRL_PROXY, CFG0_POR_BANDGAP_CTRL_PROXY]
0x1A084 CFG0_POR_POKLVB_UV_CTRL_PROXY reset 0x80000000
  [31] POR_POKLVB_UV_CTRL_HYST_EN_PROXY — Enable POK hysteresis
  [7] POR_POKLVB_UV_CTRL_OVER_VOLT_DET_PROXY — Over / under voltage detection mode 0 - Under voltage detection 1 - Over voltage detection
  [6:0] POR_POKLVB_UV_CTRL_POK_TRIM_PROXY — POK trim bits. These bits are used to trim the comparator threshold voltage. See POK spec and J7 efuse spec for details
0x1A088 CFG0_POR_POKLVA_OV_CTRL_PROXY reset 0x80000000
  [31] POR_POKLVA_OV_CTRL_HYST_EN_PROXY — Enable POK hysteresis
  [7] POR_POKLVA_OV_CTRL_OVER_VOLT_DET_PROXY — Over / under voltage detection mode 0 - Under voltage detection 1 - Over voltage detection
  [6:0] POR_POKLVA_OV_CTRL_POK_TRIM_PROXY — POK trim bits. These bits are used to trim the comparator threshold voltage. See POK spec and J7 efuse spec for details
0x1A08C CFG0_POR_BANDGAP_CTRL_PROXY
  [19:16] POR_BANDGAP_CTRL_BGAPI_PROXY — Bandgap output current trim bits
  [15:8] POR_BANDGAP_CTRL_BGAPV_PROXY — Bandgap output voltage magnitude trim bits
  [7:0] POR_BANDGAP_CTRL_BGAPC_PROXY — Bandgap slope trim bits. Bit7 is used to calculate the offset
